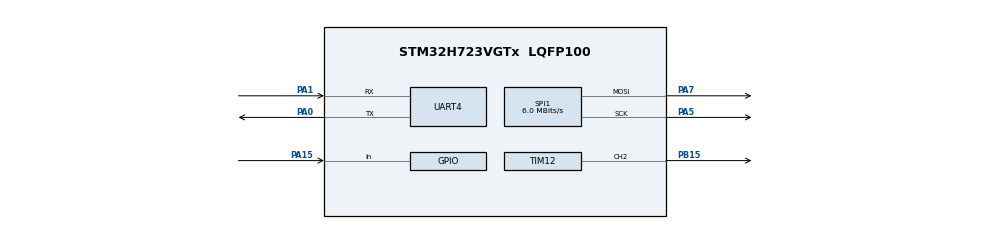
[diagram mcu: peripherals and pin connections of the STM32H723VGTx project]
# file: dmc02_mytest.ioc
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CORTEX_M7.CPU_ICache=Enabled
CORTEX_M7.default_mode_Activation=1
Dma.Request0=SPI1_TX
Dma.Request1=UART4_TX
Dma.SPI1_TX.0.Direction=DMA_MEMORY_TO_PERIPH
Dma.SPI1_TX.0.EventEnable=DISABLE
Dma.SPI1_TX.0.FIFOMode=DMA_FIFOMODE_DISABLE
Dma.SPI1_TX.0.Instance=DMA1_Stream0
Dma.SPI1_TX.0.MemDataAlignment=DMA_MDATAALIGN_BYTE
Dma.SPI1_TX.0.MemInc=DMA_MINC_ENABLE
Dma.SPI1_TX.0.Mode=DMA_NORMAL
Dma.SPI1_TX.0.PeriphDataAlignment=DMA_PDATAALIGN_BYTE
Dma.SPI1_TX.0.PeriphInc=DMA_PINC_DISABLE
Dma.SPI1_TX.0.Polarity=HAL_DMAMUX_REQ_GEN_RISING
Dma.SPI1_TX.0.Priority=DMA_PRIORITY_LOW
Dma.SPI1_TX.0.RequestNumber=1
Dma.SPI1_TX.0.SignalID=NONE
Dma.SPI1_TX.0.SyncEnable=DISABLE
Dma.SPI1_TX.0.SyncPolarity=HAL_DMAMUX_SYNC_NO_EVENT
Dma.SPI1_TX.0.SyncRequestNumber=1
Dma.SPI1_TX.0.SyncSignalID=NONE
Dma.UART4_TX.1.Direction=DMA_MEMORY_TO_PERIPH
Dma.UART4_TX.1.EventEnable=DISABLE
Dma.UART4_TX.1.FIFOMode=DMA_FIFOMODE_DISABLE
Dma.UART4_TX.1.Instance=DMA1_Stream1
Dma.UART4_TX.1.MemDataAlignment=DMA_MDATAALIGN_BYTE
Dma.UART4_TX.1.MemInc=DMA_MINC_ENABLE
Dma.UART4_TX.1.Mode=DMA_NORMAL
Dma.UART4_TX.1.PeriphDataAlignment=DMA_PDATAALIGN_BYTE
Dma.UART4_TX.1.PeriphInc=DMA_PINC_DISABLE
Dma.UART4_TX.1.Polarity=HAL_DMAMUX_REQ_GEN_RISING
Dma.UART4_TX.1.Priority=DMA_PRIORITY_LOW
Dma.UART4_TX.1.RequestNumber=1
Dma.UART4_TX.1.SignalID=NONE
Dma.UART4_TX.1.SyncEnable=DISABLE
Dma.UART4_TX.1.SyncPolarity=HAL_DMAMUX_SYNC_NO_EVENT
Dma.UART4_TX.1.SyncRequestNumber=1
Dma.UART4_TX.1.SyncSignalID=NONE
Mcu.Family=STM32H7
Mcu.Name=STM32H723VGTx
Mcu.Package=LQFP100
NVIC.DMA1_Stream0_IRQn=true\:0\:0\:false\:false\:true\:false\:true\:true
NVIC.DMA1_Stream1_IRQn=true\:0\:0\:false\:false\:true\:false\:true\:true
NVIC.PriorityGroup=NVIC_PRIORITYGROUP_4
NVIC.SPI1_IRQn=true\:0\:0\:false\:false\:true\:true\:true\:true
NVIC.TIM6_DAC_IRQn=true\:15\:0\:false\:false\:true\:false\:true\:true
NVIC.TIM8_BRK_TIM12_IRQn=true\:0\:0\:false\:false\:true\:true\:true\:true
NVIC.TimeBase=TIM6_DAC_IRQn
NVIC.TimeBaseIP=TIM6
NVIC.UART4_IRQn=true\:0\:0\:false\:false\:true\:true\:true\:true
PA0.Mode=Asynchronous
PA0.Signal=UART4_TX
PA1.Mode=Asynchronous
PA1.Signal=UART4_RX
PA13(JTMS/SWDIO).Mode=Serial_Wire
PA13(JTMS/SWDIO).Signal=DEBUG_JTMS-SWDIO
PA14(JTCK/SWCLK).Mode=Serial_Wire
PA14(JTCK/SWCLK).Signal=DEBUG_JTCK-SWCLK
PA15(JTDI).GPIO_PuPd=GPIO_PULLUP
PA15(JTDI).Signal=GPIO_Input
PA5.Mode=TX_Only_Simplex_Unidirect_Master
PA5.Signal=SPI1_SCK
PA7.Mode=TX_Only_Simplex_Unidirect_Master
PA7.Signal=SPI1_MOSI
PB15.Signal=S_TIM12_CH2
PH0-OSC_IN.Mode=HSE-External-Oscillator
PH0-OSC_IN.Signal=RCC_OSC_IN
PH1-OSC_OUT.Mode=HSE-External-Oscillator
PH1-OSC_OUT.Signal=RCC_OSC_OUT
ProjectManager.HeapSize=0x200
ProjectManager.StackSize=0x400
ProjectManager.TargetToolchain=CMake
RCC.ADCFreq_Value=192000000
RCC.APB1Freq_Value=137500000
RCC.APB2Freq_Value=137500000
RCC.APB3Freq_Value=137500000
RCC.APB4Freq_Value=137500000
RCC.CortexFreq_Value=550000000
RCC.D1PPRE=RCC_APB3_DIV2
RCC.D2PPRE1=RCC_APB1_DIV2
RCC.D2PPRE2=RCC_APB2_DIV2
RCC.D3PPRE=RCC_APB4_DIV2
RCC.DIVM1=3
RCC.DIVM2=2
RCC.DIVN1=68
RCC.DIVN2=16
RCC.DIVP1=1
RCC.DIVP2=1
RCC.DIVQ1=3
RCC.HCLKFreq_Value=275000000
RCC.HPRE=RCC_HCLK_DIV2
RCC.HSE_VALUE=24000000
RCC.PLL2FRACN=0
RCC.PLL3FRACN=0
RCC.PLLFRACN=6144
RCC.PLLSourceVirtual=RCC_PLLSOURCE_HSE
RCC.SPI123CLockSelection=RCC_SPI123CLKSOURCE_PLL2
RCC.SYSCLKFreq_VALUE=550000000
RCC.SYSCLKSource=RCC_SYSCLKSOURCE_PLLCLK
RCC.USBFreq_Value=183333333.33333334
SH.S_TIM12_CH2.0=TIM12_CH2,PWM Generation2 CH2
SPI1.BaudRatePrescaler=SPI_BAUDRATEPRESCALER_32
SPI1.CalculateBaudRate=6.0 MBits/s
SPI1.DataSize=SPI_DATASIZE_8BIT
SPI1.Direction=SPI_DIRECTION_2LINES_TXONLY
SPI1.MasterKeepIOState=SPI_MASTER_KEEP_IO_STATE_ENABLE
SPI1.Mode=SPI_MODE_MASTER
SPI1.VirtualType=VM_MASTER
TIM12.Channel-PWM\ Generation2\ CH2=TIM_CHANNEL_2
TIM12.Period=100
TIM12.Prescaler=550
VP_MEMORYMAP_VS_MEMORYMAP.Mode=CurAppReg
VP_SYS_VS_tim6.Mode=TIM6
VP_TIM12_VS_ClockSourceINT.Mode=Internal
board=custom

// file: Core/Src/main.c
/* USER CODE BEGIN Header */
/**
  ******************************************************************************
  * @file           : main.c
  * @brief          : Main program body
  ******************************************************************************
  * @attention
  *
  * Copyright (c) 2026 STMicroelectronics.
  * All rights reserved.
  *
  * This software is licensed under terms that can be found in the LICENSE file
  * in the root directory of this software component.
  * If no LICENSE file comes with this software, it is provided AS-IS.
  *
  ******************************************************************************
  */
/* USER CODE END Header */
#include "main.h"
#include "dma.h"
#include "spi.h"
#include "tim.h"
#include "usart.h"
#include "gpio.h"

/* USER CODE BEGIN Includes */
#include "User/middlewares/devices/ws2812/ws2812.h"
#include "User/middlewares/Algorithm/music/Music.h"
/* USER CODE END Includes */

void SystemClock_Config(void);
static void MPU_Config(void);

int main(void)
{

  /* MPU Configuration--------------------------------------------------------*/
  MPU_Config();

  /* Enable the CPU Cache */

  /* Enable I-Cache---------------------------------------------------------*/
  SCB_EnableICache();

  /* MCU Configuration--------------------------------------------------------*/

  /* Reset of all peripherals, Initializes the Flash interface and the Systick. */
  HAL_Init();

  /* Configure the system clock */
  SystemClock_Config();

  /* Initialize all configured peripherals */
  MX_GPIO_Init();
  MX_DMA_Init();
  MX_SPI1_Init();
  MX_TIM12_Init();
  MX_UART4_Init();

  /* Infinite loop */
  /* USER CODE BEGIN WHILE */
  WS2812_Init();
  HAL_TIM_PWM_Start(&htim12, TIM_CHANNEL_2);

  while (1)
  {
    music_start();

    /* USER CODE END WHILE */

  }
}

void SystemClock_Config(void)
{
  RCC_OscInitTypeDef RCC_OscInitStruct = {0};
  RCC_ClkInitTypeDef RCC_ClkInitStruct = {0};

  /** Supply configuration update enable
  */
  HAL_PWREx_ConfigSupply(PWR_LDO_SUPPLY);

  /** Configure the main internal regulator output voltage
  */
  __HAL_PWR_VOLTAGESCALING_CONFIG(PWR_REGULATOR_VOLTAGE_SCALE0);

  while(!__HAL_PWR_GET_FLAG(PWR_FLAG_VOSRDY)) {}

  /** Initializes the RCC Oscillators according to the specified parameters
  * in the RCC_OscInitTypeDef structure.
  */
  RCC_OscInitStruct.OscillatorType = RCC_OSCILLATORTYPE_HSE;
  RCC_OscInitStruct.HSEState = RCC_HSE_ON;
  RCC_OscInitStruct.PLL.PLLState = RCC_PLL_ON;
  RCC_OscInitStruct.PLL.PLLSource = RCC_PLLSOURCE_HSE;
  RCC_OscInitStruct.PLL.PLLM = 3;
  RCC_OscInitStruct.PLL.PLLN = 68;
  RCC_OscInitStruct.PLL.PLLP = 1;
  RCC_OscInitStruct.PLL.PLLQ = 3;
  RCC_OscInitStruct.PLL.PLLR = 2;
  RCC_OscInitStruct.PLL.PLLRGE = RCC_PLL1VCIRANGE_3;
  RCC_OscInitStruct.PLL.PLLVCOSEL = RCC_PLL1VCOWIDE;
  RCC_OscInitStruct.PLL.PLLFRACN = 6144;
  if (HAL_RCC_OscConfig(&RCC_OscInitStruct) != HAL_OK)
  {
    Error_Handler();
  }

  /** Initializes the CPU, AHB and APB buses clocks
  */
  RCC_ClkInitStruct.ClockType = RCC_CLOCKTYPE_HCLK|RCC_CLOCKTYPE_SYSCLK
                              |RCC_CLOCKTYPE_PCLK1|RCC_CLOCKTYPE_PCLK2
                              |RCC_CLOCKTYPE_D3PCLK1|RCC_CLOCKTYPE_D1PCLK1;
  RCC_ClkInitStruct.SYSCLKSource = RCC_SYSCLKSOURCE_PLLCLK;
  RCC_ClkInitStruct.SYSCLKDivider = RCC_SYSCLK_DIV1;
  RCC_ClkInitStruct.AHBCLKDivider = RCC_HCLK_DIV2;
  RCC_ClkInitStruct.APB3CLKDivider = RCC_APB3_DIV2;
  RCC_ClkInitStruct.APB1CLKDivider = RCC_APB1_DIV2;
  RCC_ClkInitStruct.APB2CLKDivider = RCC_APB2_DIV2;
  RCC_ClkInitStruct.APB4CLKDivider = RCC_APB4_DIV2;

  if (HAL_RCC_ClockConfig(&RCC_ClkInitStruct, FLASH_LATENCY_3) != HAL_OK)
  {
    Error_Handler();
  }
}

 /* MPU Configuration */

void MPU_Config(void)
{
  MPU_Region_InitTypeDef MPU_InitStruct = {0};

  /* Disables the MPU */
  HAL_MPU_Disable();

  /** Initializes and configures the Region and the memory to be protected
  */
  MPU_InitStruct.Enable = MPU_REGION_ENABLE;
  MPU_InitStruct.Number = MPU_REGION_NUMBER0;
  MPU_InitStruct.BaseAddress = 0x0;
  MPU_InitStruct.Size = MPU_REGION_SIZE_4GB;
  MPU_InitStruct.SubRegionDisable = 0x87;
  MPU_InitStruct.TypeExtField = MPU_TEX_LEVEL0;
  MPU_InitStruct.AccessPermission = MPU_REGION_NO_ACCESS;
  MPU_InitStruct.DisableExec = MPU_INSTRUCTION_ACCESS_DISABLE;
  MPU_InitStruct.IsShareable = MPU_ACCESS_SHAREABLE;
  MPU_InitStruct.IsCacheable = MPU_ACCESS_NOT_CACHEABLE;
  MPU_InitStruct.IsBufferable = MPU_ACCESS_NOT_BUFFERABLE;

  HAL_MPU_ConfigRegion(&MPU_InitStruct);
  /* Enables the MPU */
  HAL_MPU_Enable(MPU_PRIVILEGED_DEFAULT);

}

void HAL_TIM_PeriodElapsedCallback(TIM_HandleTypeDef *htim)
{
  if (htim->Instance == TIM6)
  {
    HAL_IncTick();
  }
}

void Error_Handler(void)
{
  __disable_irq();
  while (1)
  {
  }
}
